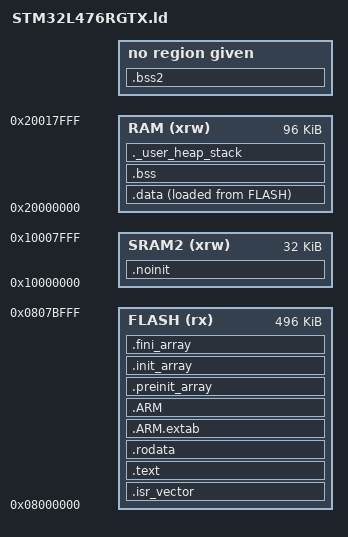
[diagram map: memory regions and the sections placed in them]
/*
*****************************************************************************
**

**  File        : LinkerScript.ld
**
**  Abstract    : Linker script for STM32L476RGTx Device with
**                1024KByte FLASH, 96KByte RAM
**
**                Set heap size, stack size and stack location according
**                to application requirements.
**
**                Set memory bank area and size if external memory is used.
**
**  Target      : STMicroelectronics STM32
**
**
**  Distribution: The file is distributed as is, without any warranty
**                of any kind.
**
**  (c)Copyright Ac6.
**  You may use this file as-is or modify it according to the needs of your
**  project. Distribution of this file (unmodified or modified) is not
**  permitted. Ac6 permit registered System Workbench for MCU users the
**  rights to distribute the assembled, compiled & linked contents of this
**  file as part of an application binary file, provided that it is built
**  using the System Workbench for MCU toolchain.
**
*****************************************************************************
*/

ENTRY(Reset_Handler)

_estack = 0x20018000;

_Min_Heap_Size = 0x1000;
_Min_Stack_Size = 0x2000;

MEMORY
{
FLASH (rx)      : ORIGIN = 0x08000000, LENGTH = 496K
RAM (xrw)      : ORIGIN = 0x20000000, LENGTH = 96K
SRAM2 (xrw)     : ORIGIN = 0x10000000, LENGTH = 32K
}

SECTIONS
{

  .isr_vector :
  {
    . = ALIGN(8);
    KEEP(*(.isr_vector))
    . = ALIGN(8);
  } >FLASH

  .text :
  {
    . = ALIGN(8);
    *(.text)
    *(.text*)
    *(.glue_7)
    *(.glue_7t)
    *(.eh_frame)

    KEEP (*(.init))
    KEEP (*(.fini))

    . = ALIGN(8);
    _etext = .;
  } >FLASH

  .rodata :
  {
    . = ALIGN(8);
    *(.rodata)
    *(.rodata*)
    . = ALIGN(8);
  } >FLASH

  .ARM.extab   : { *(.ARM.extab* .gnu.linkonce.armextab.*) } >FLASH
  .ARM : {
    __exidx_start = .;
    *(.ARM.exidx*)
    __exidx_end = .;
  } >FLASH

  .preinit_array (READONLY) :
  {
    PROVIDE_HIDDEN (__preinit_array_start = .);
    KEEP (*(.preinit_array*))
    PROVIDE_HIDDEN (__preinit_array_end = .);
  } >FLASH
  .init_array (READONLY) :
  {
    PROVIDE_HIDDEN (__init_array_start = .);
    KEEP (*(SORT(.init_array.*)))
    KEEP (*(.init_array*))
    PROVIDE_HIDDEN (__init_array_end = .);
  } >FLASH
  .fini_array (READONLY) :
  {
    PROVIDE_HIDDEN (__fini_array_start = .);
    KEEP (*(SORT(.fini_array.*)))
    KEEP (*(.fini_array*))
    PROVIDE_HIDDEN (__fini_array_end = .);
  } >FLASH

  _sidata = LOADADDR(.data);

  .data :
  {
    . = ALIGN(8);
    _sdata = .;
    *(.data)
    *(.data*)

    . = ALIGN(8);
    _edata = .;
  } >RAM AT> FLASH

  . = ALIGN(4);
  .bss :
  {

    _sbss = .;
    __bss_start__ = _sbss;
    *(.bss)
    *(.bss*)
    *(COMMON)

    . = ALIGN(4);
    _ebss = .;
    __bss_end__ = _ebss;
  } >RAM

  .noinit (NOLOAD) :
  {
    . = ALIGN(4);
    *(.noinit)
    . = ALIGN(4);
  } >SRAM2

  .bss2 (NOLOAD) : AT (0x10000000)
  {
    . = ALIGN(4);
    _sbss2 = .;
    *(.bss2)
    _ebss2 = .;
  }

  ._user_heap_stack :
  {
    . = ALIGN(4);
    PROVIDE ( end = . );
    PROVIDE ( _end = . );
    . = . + _Min_Heap_Size;
    . = . + _Min_Stack_Size;
    . = ALIGN(4);
  } >RAM

  /DISCARD/ :
  {
    libc.a ( * )
    libm.a ( * )
    libgcc.a ( * )
  }

  .ARM.attributes 0 : { *(.ARM.attributes) }
}
